# N32H7xx register map
Vendor: Nationstech Ltd.; File version: 1.0
Registers are 32-bit, read-write, reset 0x0 unless marked. A register's access mark holds for its fields unless they carry their own. Offsets are from the block's base; [hi:lo] are bit positions; {n}, {i} and the like mark numbered series; 'fields as' and 'values as' point back to an identical list.

## TCMC — Tightly Coupled Memory Controller
Base 0x5004B000
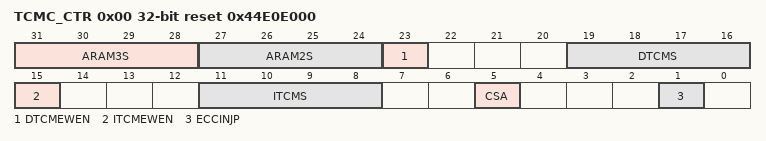
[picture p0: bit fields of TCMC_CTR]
0x00 TCMC_CTR reset 0x44E0E000 — TCMC control register
  [31:28] ARAM3S, [27:24] ARAM2S, [23] DTCMEWEN, [19:16] DTCMS, [15] ITCMEWEN, [11:8] ITCMS, [5] CSA, [1] ECCINJP

## JPEGCTRL — JPEG mode CTRL
Base 0x50090800
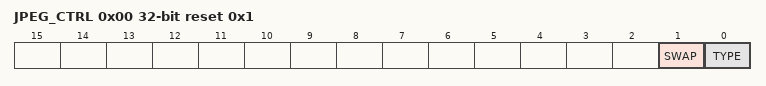
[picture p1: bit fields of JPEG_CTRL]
0x00 JPEG_CTRL reset 0x1 — JPEG mode CTRL
  [1] SWAP, [0] TYPE

## BRC — peripherals to Host
Base 0x50090000
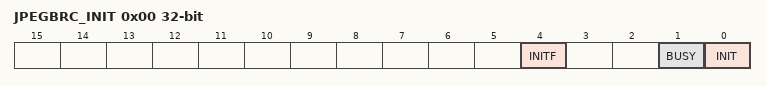
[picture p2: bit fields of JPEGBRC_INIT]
0x00 JPEGBRC_INIT — Core init
  [4] INITF, [1] BUSY, [0] INIT
0x04 JPEGBRC_EN — Core Enable
  [0] EN
0x08 JPEGBRC_BUFBADDR — AXI buffer base address
  [31:0] ADDR
0x0C JPEGBRC_BUFSIZE — AXI buffer size
  [15:0] SIZE
0x44 JPEGBRC_USMODE — Up sampling mode
  [1:0] MODE

## RBC — Host to peripherals
Base 0x50070000
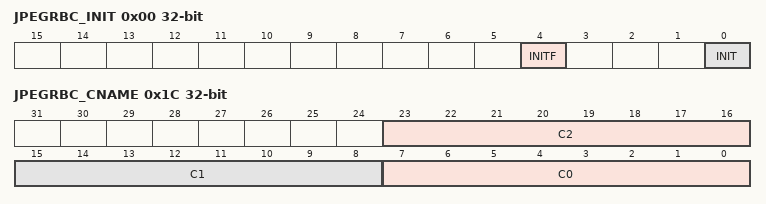
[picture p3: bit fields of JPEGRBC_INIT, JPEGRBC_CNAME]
0x00 JPEGRBC_INIT — Core init
  [4] INITF, [0] INIT
0x04 JPEGRBC_EN — Core enable
  [0] EN
0x08 JPEGRBC_SWITCH reset 0x1 — Switch input sample order
  [0] SWITCH
0x0C JPEGRBC_FRMW reset 0x3FFFF — Frame width
  [15:0] WIDTH
0x10 JPEGRBC_FRMH reset 0xFFFF — Frame height
  [15:0] HEIGHT
0x18 JPEGRBC_PFORM — Pixel format
  [2:0] FORMAT
0x1C JPEGRBC_CNAME — Component names
  [23:16] C2, [15:8] C1, [7:0] C0
0x20 JPEGRBC_C0SADD — Component 0 start address
  [31:0] ADDR
0x24 JPEGRBC_C0EADD — Component 0 end address
  [9:0] ADDR
0x60 JPEGRBC_BPS0 — Blocks per Scan 0
  [27:0] NUM
0x64 JPEGRBC_BPS12 — Blocks per Scan 1,2
  [27:0] NUM
0x68 JPEGRBC_ROWS0 — MCU rows Scan 0
  [12:0] NUM
0x6C JPEGRBC_ROWS12 — MCU rows Scan 1,2
  [12:0] NUM
0x70 JPEGRBC_HHALF — Frame height half
  [14:0] HHALF
0x74 JPEGRBC_BLSS0 — Block line stride Scan 0
  [17:0] SIZE
0x78 JPEGRBC_BLSS12 — Block line stride Scan 1,2
  [17:0] SIZE
0x7C JPEGRBC_BPRS0 — Blocks per MCU row Scan 0
  [14:0] NUM
0x80 JPEGRBC_BPRS12 — Blocks per MCU row Scan 1,2
  [14:0] NUM
0x84 JPEGRBC_MAXW reset 0xFFFF — Maximum supported width
  [31:0] WIDTH
0x88 JPEGRBC_MAXH reset 0x10000 — Maximum supported height
  [31:0] HEIGHT
0x8C JPEGRBC_MBSIZE reset 0xFFFF — Maximum supported buffer size
  [31:0] SIZE

## ENC — Host to peripherals
Base 0x50060000
0x4800 JPEGENC_HEADD — End address of JPEG header 1st part
  [9:0] ADDR
{0x4814+4i} JPEGENC_HUFTAB{i}E (i=0..3) — End address of Huffman table {i}
  [9:0] ADDR
0x4824 JPEGENC_FEADD — End address of JPEG footer
  [9:0] ADDR
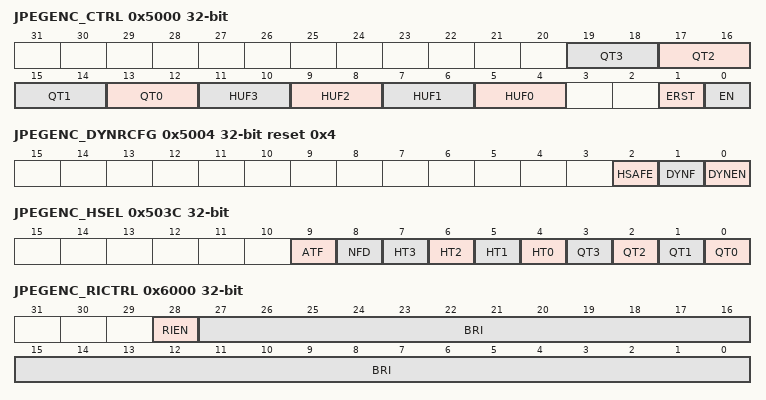
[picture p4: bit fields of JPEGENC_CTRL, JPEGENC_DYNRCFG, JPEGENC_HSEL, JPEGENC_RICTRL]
0x5000 JPEGENC_CTRL — Core control register
  [2n+13:2n+12] QT{n} (n=0..3), [2n+5:2n+4] HUF{n} (n=0..3), [1] ERST, [0] EN
0x5004 JPEGENC_DYNRCFG reset 0x4 — Dynamic reconfiguration register
  [2] HSAFE, [1] DYNF, [0] DYNEN
0x503C JPEGENC_HSEL — Header parts select
  [9] ATF, [8] NFD, [n+4] HT{n} (n=0..3), [n] QT{n} (n=0..3)
0x5100 JPEGENC_PIPESTS — Status Register Pipe
  [0] OOVF
0x6000 JPEGENC_RICTRL — Restart interval control register
  [28] RIEN, [27:0] BRI
0xA004 JPEGENC_HFSIZE reset 0x400 — Header/footer ram size
  [31:0] SIZE
0xA024 JPEGENC_OBSIZE — Output buffer size
  [31:0] SIZE

## DEC — peripherals to Host
Base 0x50080000
0x00 JPEGDEC_MODE — Mode
  [0] EN
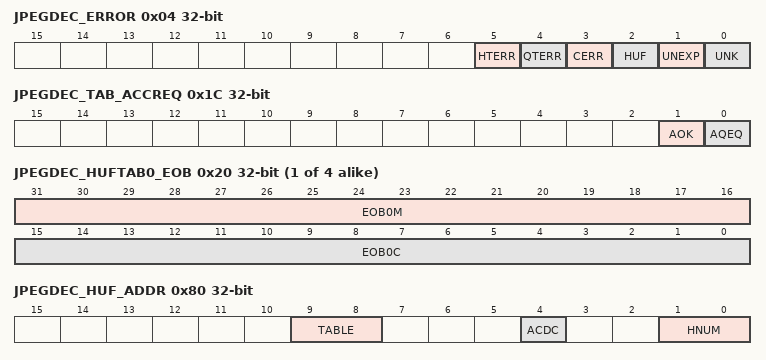
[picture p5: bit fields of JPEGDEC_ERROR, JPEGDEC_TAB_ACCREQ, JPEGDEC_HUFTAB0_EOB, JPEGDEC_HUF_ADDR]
0x04 JPEGDEC_ERROR — Error register
  [5] HTERR, [4] QTERR, [3] CERR, [2] HUF, [1] UNEXP, [0] UNK
0x08 JPEGDEC_UNLOC — Unknown marker error location (write 0 to clear, write 1 keeps current value)
  [31:0] POS
0x0C JPEGDEC_UELOC — In the event of an unexpected marker error, the decoder stores the location of the unexpected marker in this register. The location is the byte-offset from the last SOI marker processed.
  [31:0] POS
0x10 JPEGDEC_HESYM — Huffman error symbol
  [15:0] HESYM
0x14 JPEGDEC_HESYMECS — ECS number of Huffman symbol error
  [31:0] NUM
0x18 JPEGDEC_HUF_SELOC — Huffman symbol error location in ECS
  [31:0] POS
0x1C JPEGDEC_TAB_ACCREQ — Table access request
  [1] AOK, [0] AQEQ
{0x20+4i} JPEGDEC_HUFTAB{i}_EOB (i=0..3) — Huffman table {i} EOB symbol
  [31:16] EOB{i}M, [15:0] EOB{i}C
0x80 JPEGDEC_HUF_ADDR — Huffman table access address
  [9:8] TABLE, [4] ACDC, [1:0] HNUM
0x84 JPEGDEC_HUF_DATA — Huffman table access data
  [31:0] HDATA
0x88 JPEGDEC_HUF_REM — Huffman table access number of words remaining from the currently selected Huffman table
  [31:0] HREM

## DBG — Debug
Base 0x58035400
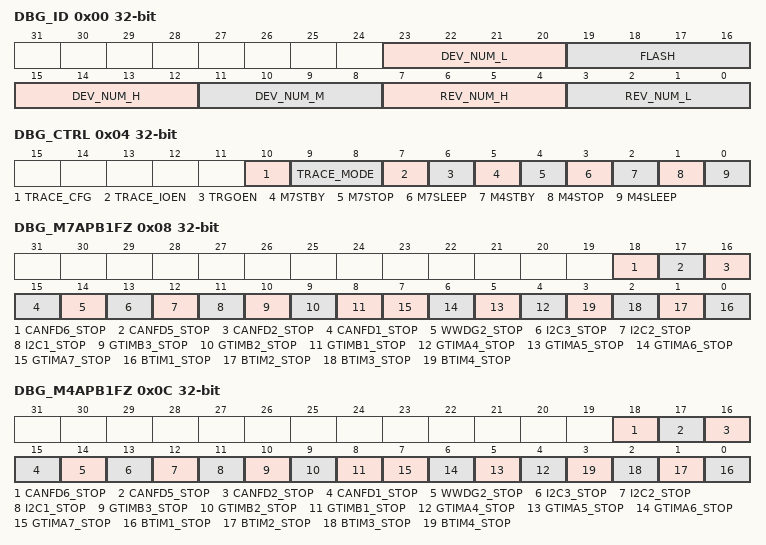
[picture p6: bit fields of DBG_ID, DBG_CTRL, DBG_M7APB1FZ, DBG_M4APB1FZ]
0x00 DBG_ID ro — DBGMCU Identity code register
  [23:20] DEV_NUM_L
  [19:16] FLASH — FLASH capacity
  [15:12] DEV_NUM_H
  [11:8] DEV_NUM_M
  [7:4] REV_NUM_H
  [3:0] REV_NUM_L
0x04 DBG_CTRL — Control Register
  [10] TRACE_CFG, [9:8] TRACE_MODE, [7] TRACE_IOEN, [6] TRGOEN, [5] M7STBY, [4] M7STOP, [3] M7SLEEP, [2] M4STBY, [1] M4STOP, [0] M4SLEEP
0x08 DBG_M7APB1FZ — DBGMCU APB1 peripheral freeze register CPU1
  [18] CANFD6_STOP, [17] CANFD5_STOP, [16] CANFD2_STOP, [15] CANFD1_STOP, [14] WWDG2_STOP, [13] I2C3_STOP, [12] I2C2_STOP, [11] I2C1_STOP, [10] GTIMB3_STOP, [9] GTIMB2_STOP, [8] GTIMB1_STOP, [n] GTIMA{n}_STOP (n=4..7), [n-1] BTIM{n}_STOP (n=1..4)
0x0C DBG_M4APB1FZ — DBGMCU APB1 peripheral freeze register CPU2
  fields as DBG_M7APB1FZ
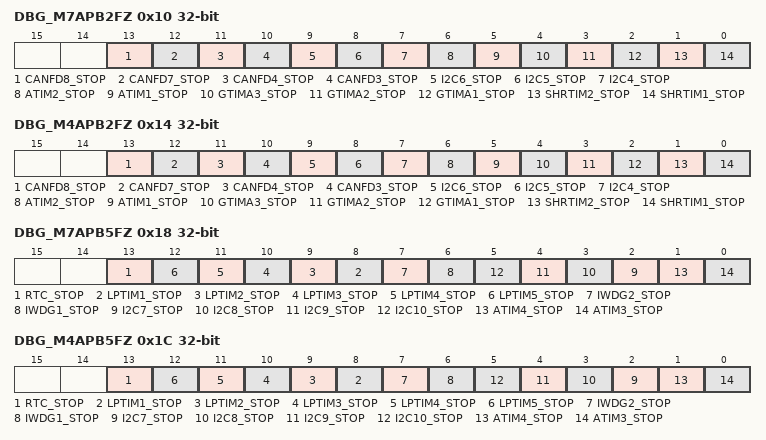
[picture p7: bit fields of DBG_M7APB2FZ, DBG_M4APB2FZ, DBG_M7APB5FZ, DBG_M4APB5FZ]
0x10 DBG_M7APB2FZ — DBGMCU APB2 peripheral freeze register CPU1
  [13] CANFD8_STOP, [12] CANFD7_STOP, [11] CANFD4_STOP, [10] CANFD3_STOP, [9] I2C6_STOP, [8] I2C5_STOP, [7] I2C4_STOP, [6] ATIM2_STOP, [5] ATIM1_STOP, [4] GTIMA3_STOP, [3] GTIMA2_STOP, [2] GTIMA1_STOP, [1] SHRTIM2_STOP, [0] SHRTIM1_STOP
0x14 DBG_M4APB2FZ — DBGMCU APB2 peripheral freeze register CPU2
  fields as DBG_M7APB2FZ
0x18 DBG_M7APB5FZ — DBGMCU APB5 peripheral freeze register CPU1
  [13] RTC_STOP, [n+7] LPTIM{n}_STOP (n=1..5), [7] IWDG2_STOP, [6] IWDG1_STOP, [n-5] I2C{n}_STOP (n=7..10), [1] ATIM4_STOP, [0] ATIM3_STOP
0x1C DBG_M4APB5FZ — DBGMCU APB5 peripheral freeze register CPU2
  fields as DBG_M7APB5FZ
0x20 DBG_M7APB6FZ — DBGMCU APB6 peripheral freeze register CPU1
  [0] WWDG1_STOP
0x24 DBG_M4APB6FZ — DBGMCU APB6 peripheral freeze register CPU2
  [0] WWDG1_STOP

## DVP1 — Digital video port
Base 0x50048000
Same registers: DVP2 0x50049000
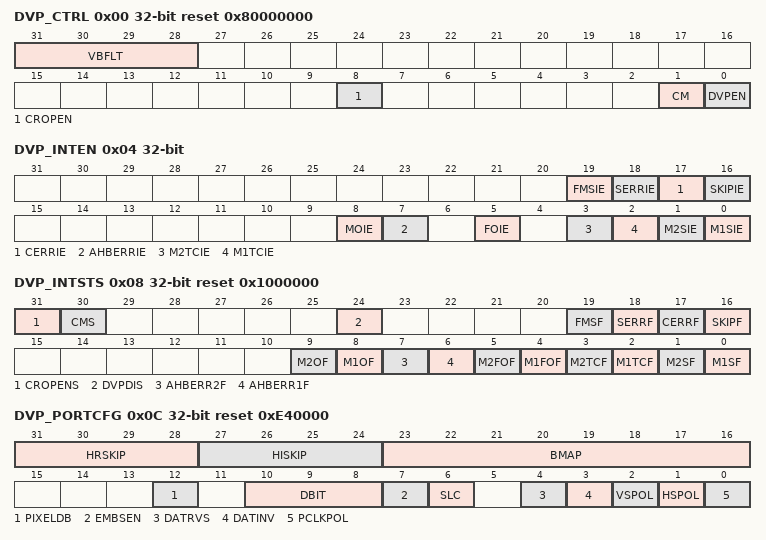
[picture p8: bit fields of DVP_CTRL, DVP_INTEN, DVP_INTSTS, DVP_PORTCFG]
0x00 DVP_CTRL reset 0x80000000
  [31:28] VBFLT, [8] CROPEN, [1] CM, [0] DVPEN
0x04 DVP_INTEN
  [19] FMSIE, [18] SERRIE, [17] CERRIE, [16] SKIPIE, [8] MOIE, [7] AHBERRIE, [5] FOIE, [3] M2TCIE, [2] M1TCIE, [1] M2SIE, [0] M1SIE
0x08 DVP_INTSTS reset 0x1000000
  [31] CROPENS ro, [30] CMS ro, [24] DVPDIS, [19] FMSF, [18] SERRF, [17] CERRF, [16] SKIPF, [9] M2OF, [8] M1OF, [7] AHBERR2F, [6] AHBERR1F, [5] M2FOF, [4] M1FOF, [3] M2TCF, [2] M1TCF, [1] M2SF, [0] M1SF
0x0C DVP_PORTCFG reset 0xE40000
  [31:28] HRSKIP, [27:24] HISKIP, [23:16] BMAP, [12] PIXELDB, [10:8] DBIT, [7] EMBSEN, [6] SLC, [4] DATRVS, [3] DATINV, [2] VSPOL, [1] HSPOL, [0] PCLKPOL
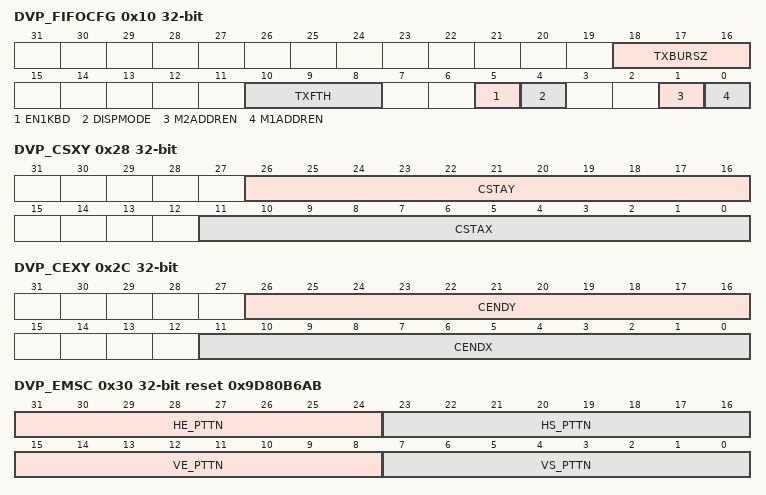
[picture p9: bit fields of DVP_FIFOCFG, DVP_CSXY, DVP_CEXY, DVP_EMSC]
0x10 DVP_FIFOCFG
  [18:16] TXBURSZ, [10:8] TXFTH, [5] EN1KBD, [4] DISPMODE, [1] M2ADDREN, [0] M1ADDREN
0x14 DVP_SMADDR1
  [31:0] MADDR
0x18 DVP_SMADDR2
  [31:0] MADDR
0x1C DVP_FBS
  [21:0] FMSIZE
0x20 DVP_FPBC1 ro
  [31:0] PIXLC
0x24 DVP_FPBC2 ro
  [31:0] PIXLC
0x28 DVP_CSXY
  [26:16] CSTAY, [11:0] CSTAX
0x2C DVP_CEXY
  [26:16] CENDY, [11:0] CENDX
0x30 DVP_EMSC reset 0x9D80B6AB
  [31:24] HE_PTTN, [23:16] HS_PTTN, [15:8] VE_PTTN, [7:0] VS_PTTN
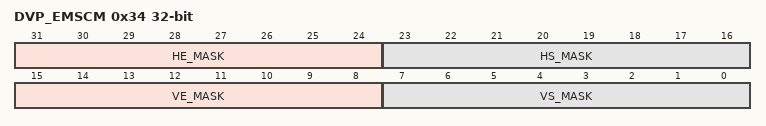
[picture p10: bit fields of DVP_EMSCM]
0x34 DVP_EMSCM
  [31:24] HE_MASK, [23:16] HS_MASK, [15:8] VE_MASK, [7:0] VS_MASK
